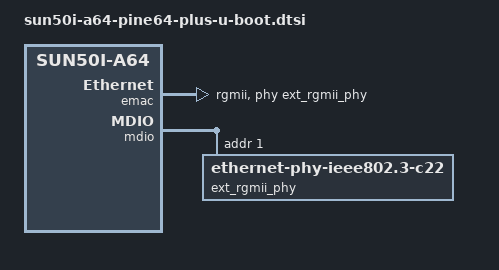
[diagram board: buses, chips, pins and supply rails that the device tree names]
/ {
	aliases {
		ethernet0 = &emac;
	};
};

&emac {
	pinctrl-names = "default";
	pinctrl-0 = <&rgmii_pins>;
	phy-mode = "rgmii";
	phy-handle = <&ext_rgmii_phy>;
	status = "okay";
};

&mdio {
	ext_rgmii_phy: ethernet-phy@1 {
		compatible = "ethernet-phy-ieee802.3-c22";
		reg = <1>;
	};
};
